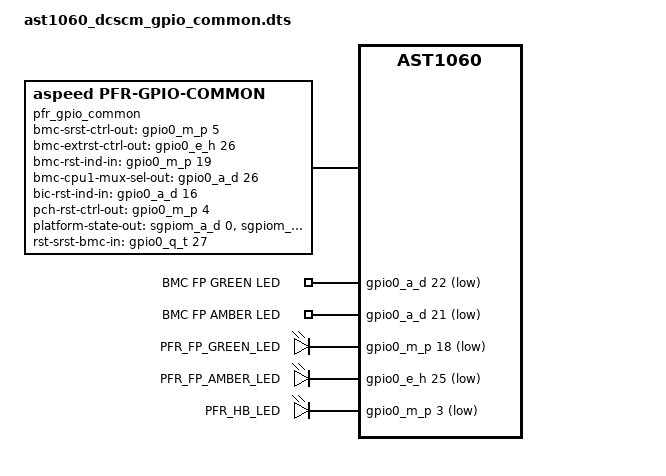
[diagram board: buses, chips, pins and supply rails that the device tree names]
#include <dt-bindings/gpio/gpio.h>

/ {
	pfr_gpio_common {
		compatible = "aspeed,pfr-gpio-common";
		bmc-srst-ctrl-out-gpios = <&gpio0_m_p 5 0>; /* GPIO_M5 */
		bmc-extrst-ctrl-out-gpios = <&gpio0_e_h 26 0>; /* GPIO_H2 */
		bmc-rst-ind-in-gpios = <&gpio0_m_p 19 0>; /* GPIO_O3 */
		bmc-cpu1-mux-sel-out-gpios = <&gpio0_a_d 26 0>; /* GPIO_D2 */
		bic-rst-ind-in-gpios = <&gpio0_a_d 16 0>; /* GPIO_C0 */
		pch-rst-ctrl-out-gpios = <&gpio0_m_p 4 0>; /* GPIO_M4 */

		platform-state-out-gpios =
			<&sgpiom_a_d 0 0>, <&sgpiom_a_d 1 0>,
			<&sgpiom_a_d 2 0>, <&sgpiom_a_d 3 0>,
			<&sgpiom_a_d 4 0>, <&sgpiom_a_d 5 0>,
			<&sgpiom_a_d 6 0>, <&sgpiom_a_d 7 0>;

		/* NOTICE:
		 * Normally, these two pin should be GPIO_ACTIVE_LOW, but currently this EVB
		 * doesn't produce correct power sequence by itself.
		 */
		rst-srst-bmc-in-gpios = <&gpio0_q_t 27 GPIO_ACTIVE_HIGH>; /* GPIO_T3 */
		rst-rsmrst-in-gpios = <&gpio0_q_t 24 GPIO_ACTIVE_HIGH>; /* GPIO_T0 */
	};

	aliases {
		fp-input0 = &bmc_fp_green_led_in;
		fp-input1 = &bmc_fp_amber_led_in;
	};

	gpio_keys {
		compatible = "gpio-keys";
		bmc_fp_green_led_in: fp_green_led_in {
			gpios = <&gpio0_a_d 22 1>; /* GPIO_C6 */
			label = "BMC FP GREEN LED";
		};

		bmc_fp_amber_led_in: fp_amber_led_in {
			gpios = <&gpio0_a_d 21 1>; /* GPIO_C5 */
			label = "BMC FP AMBER LED";
		};
	};

	leds {
		compatible = "gpio-leds";

		pfr_fp_green_led_out: green_led {
			gpios = <&gpio0_m_p 18 1>; /* GPIO_O2 */
			label = "PFR_FP_GREEN_LED";
		};

		pfr_fp_amber_led_out: amber_led {
			gpios = <&gpio0_e_h 25 1>; /* GPIO_H1 */
			label = "PFR_FP_AMBER_LED";
		};

		pfr_hb_led_out: hb_led {
			gpios = <&gpio0_m_p 3 1>; /* GPIO_M3 */
			label = "PFR_HB_LED";
		};
	};
};

